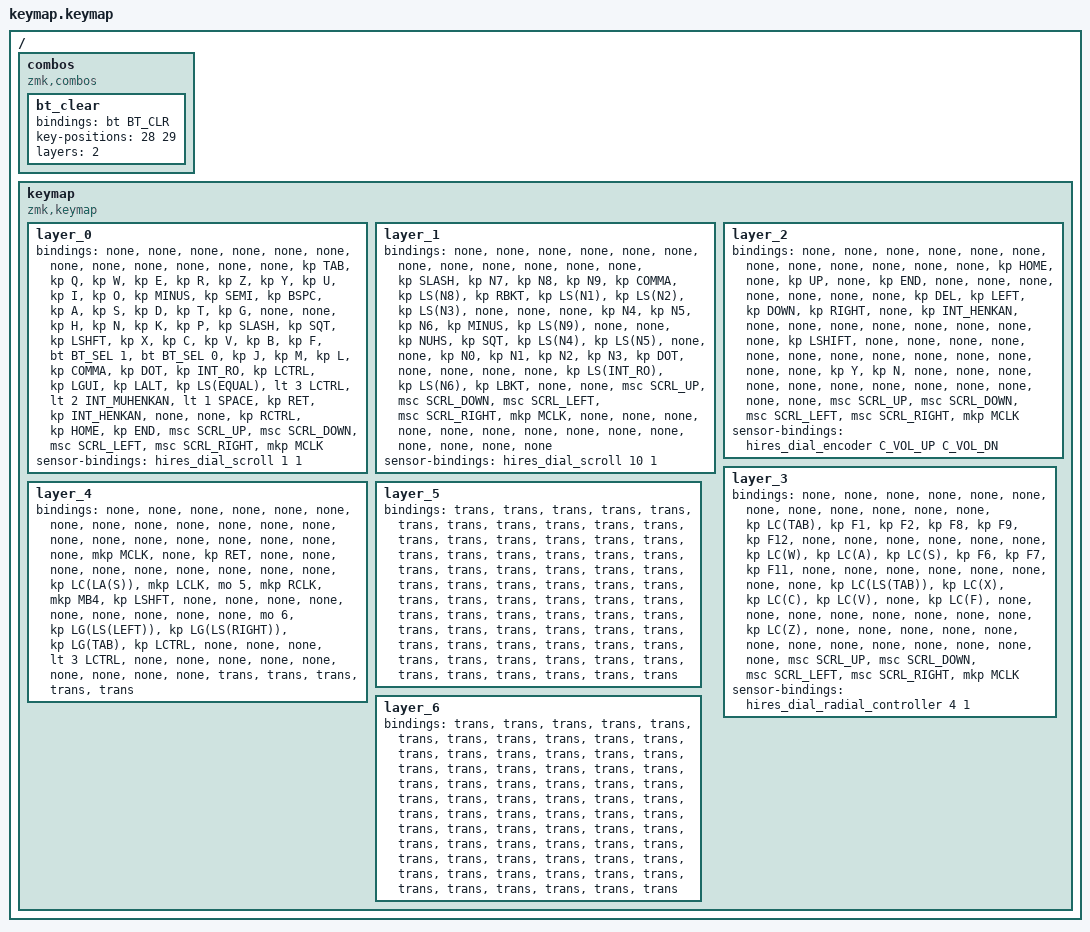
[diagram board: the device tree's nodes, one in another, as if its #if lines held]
#include <behaviors.dtsi>
#include <dt-bindings/zmk/bt.h>
#include <dt-bindings/zmk/keys.h>
#include <dt-bindings/zmk/outputs.h>
#include <dt-bindings/zmk/pointing.h>

#if defined(TORABO_TSUKI_LP_INPUT_HIRES_DIAL)
#include <behaviors/hires_dial.dtsi>
#endif

// Custom torabo-tsuki LP (M) layout.
// Layers: 0=base, 1=symbols, 2=cursor, 3=shortcuts,
// 4=auto mouse, 5=vertical scroll, 6=horizontal scroll (internal layers).
// Layout follows the stock 66-slot L-format; M has no physical number row.
// Non-mouse slots on layer 4 are &none; temp-layer processor deactivates
// the layer on a key press unless its physical position is excluded.
/ {
    combos {
        compatible = "zmk,combos";

        bt_clear {
            bindings = <&bt BT_CLR>;
            key-positions = <28 29>;
            layers = <2>;
        };
    };

    keymap {
        compatible = "zmk,keymap";

        layer_0 {
            bindings = <
            &none  &none  &none  &none  &none  &none  &none  &none  &none  &none  &none  &none
            &kp TAB  &kp Q  &kp W  &kp E  &kp R  &kp Z  &kp Y  &kp U  &kp I  &kp O  &kp MINUS  &kp SEMI
            &kp BSPC  &kp A  &kp S  &kp D  &kp T  &kp G  &none  &none  &kp H  &kp N  &kp K  &kp P  &kp SLASH  &kp SQT
            &kp LSHFT  &kp X  &kp C  &kp V  &kp B  &kp F  &bt BT_SEL 1  &bt BT_SEL 0  &kp J  &kp M  &kp L  &kp COMMA  &kp DOT  &kp INT_RO
            &kp LCTRL  &kp LGUI  &kp LALT  &kp LS(EQUAL)  &lt 3 LCTRL  &lt 2 INT_MUHENKAN  &lt 1 SPACE  &kp RET  &kp INT_HENKAN  &none  &none  &kp RCTRL  &kp HOME  &kp END
#if defined(TORABO_TSUKI_LP_KSCAN_4_DIRECTION_SWITCH)
&msc SCRL_UP &msc SCRL_DOWN &msc SCRL_LEFT &msc SCRL_RIGHT &mkp MCLK
#elif defined(TORABO_TSUKI_LP_INPUT_HIRES_DIAL)
&mkp MCLK
#endif
            >;
        };

        layer_1 {
            bindings = <
            &none  &none  &none  &none  &none  &none  &none  &none  &none  &none  &none  &none
            &kp SLASH  &kp N7  &kp N8  &kp N9  &kp COMMA  &kp LS(N8)  &kp RBKT  &kp LS(N1)  &kp LS(N2)  &kp LS(N3)  &none  &none
            &none  &kp N4  &kp N5  &kp N6  &kp MINUS  &kp LS(N9)  &none  &none  &kp NUHS  &kp SQT  &kp LS(N4)  &kp LS(N5)  &none  &none
            &kp N0  &kp N1  &kp N2  &kp N3  &kp DOT  &none  &none  &none  &none  &kp LS(INT_RO)  &kp LS(N6)  &kp LBKT  &none  &none
#if defined(TORABO_TSUKI_LP_KSCAN_4_DIRECTION_SWITCH)
&msc SCRL_UP &msc SCRL_DOWN &msc SCRL_LEFT &msc SCRL_RIGHT &mkp MCLK
#elif defined(TORABO_TSUKI_LP_INPUT_HIRES_DIAL)
&mkp MCLK
#endif
            &none  &none  &none  &none  &none  &none  &none  &none  &none  &none  &none  &none  &none  &none
            >;
        };

        layer_2 {
            bindings = <
            &none  &none  &none  &none  &none  &none  &none  &none  &none  &none  &none  &none
            &kp HOME  &none  &kp UP  &none  &kp END  &none  &none  &none  &none  &none  &none  &none
            &kp DEL  &kp LEFT  &kp DOWN  &kp RIGHT  &none  &kp INT_HENKAN  &none  &none  &none  &none  &none  &none  &none  &none
            &kp LSHIFT  &none  &none  &none  &none  &none  &none  &none  &none  &none  &none  &none  &none  &none
            &kp Y  &kp N  &none  &none  &none  &none  &none  &none  &none  &none  &none  &none  &none  &none
#if defined(TORABO_TSUKI_LP_KSCAN_4_DIRECTION_SWITCH)
&msc SCRL_UP &msc SCRL_DOWN &msc SCRL_LEFT &msc SCRL_RIGHT &mkp MCLK
#elif defined(TORABO_TSUKI_LP_INPUT_HIRES_DIAL)
&kp C_MUTE
#endif
            >;
        };

        layer_3 {
            bindings = <
            &none  &none  &none  &none  &none  &none  &none  &none  &none  &none  &none  &none
            &kp LC(TAB)  &kp F1  &kp F2  &kp F8  &kp F9  &kp F12  &none  &none  &none  &none  &none  &none
            &kp LC(W)  &kp LC(A)  &kp LC(S)  &kp F6  &kp F7  &kp F11  &none  &none  &none  &none  &none  &none  &none  &none
            &kp LC(LS(TAB))  &kp LC(X)  &kp LC(C)  &kp LC(V)  &none  &kp LC(F)  &none  &none  &none  &none  &none  &none  &none  &none
            &kp LC(Z)  &none  &none  &none  &none  &none  &none  &none  &none  &none  &none  &none  &none  &none
#if defined(TORABO_TSUKI_LP_KSCAN_4_DIRECTION_SWITCH)
&msc SCRL_UP &msc SCRL_DOWN &msc SCRL_LEFT &msc SCRL_RIGHT &mkp MCLK
#elif defined(TORABO_TSUKI_LP_INPUT_HIRES_DIAL)
&hires_dial_radial_controller_button
#endif
            >;
        };

        layer_4 {
            bindings = <
            &none  &none  &none  &none  &none  &none  &none  &none  &none  &none  &none  &none
            &none  &none  &none  &none  &none  &none  &none  &none  &none  &mkp MCLK  &none  &kp RET
            &none  &none  &none  &none  &none  &none  &none  &none  &none  &kp LC(LA(S))  &mkp LCLK  &mo 5  &mkp RCLK  &mkp MB4
            &kp LSHFT  &none  &none  &none  &none  &none  &none  &none  &none  &none  &mo 6  &kp LG(LS(LEFT))  &kp LG(LS(RIGHT))  &kp LG(TAB)
            &kp LCTRL  &none  &none  &none  &lt 3 LCTRL  &none  &none  &none  &none  &none  &none  &none  &none  &none
#if defined(TORABO_TSUKI_LP_KSCAN_4_DIRECTION_SWITCH)
&trans &trans &trans &trans &trans
#elif defined(TORABO_TSUKI_LP_INPUT_HIRES_DIAL)
&trans
#endif
            >;
        };

        // Holding the "P" position on layer 4 activates vertical-only scroll.
        layer_5 {
            bindings = <
            &trans  &trans  &trans  &trans  &trans  &trans  &trans  &trans  &trans  &trans  &trans  &trans
            &trans  &trans  &trans  &trans  &trans  &trans  &trans  &trans  &trans  &trans  &trans  &trans
            &trans  &trans  &trans  &trans  &trans  &trans  &trans  &trans  &trans  &trans  &trans  &trans  &trans  &trans
            &trans  &trans  &trans  &trans  &trans  &trans  &trans  &trans  &trans  &trans  &trans  &trans  &trans  &trans
            &trans  &trans  &trans  &trans  &trans  &trans  &trans  &trans  &trans  &trans  &trans  &trans  &trans  &trans
#if defined(TORABO_TSUKI_LP_KSCAN_4_DIRECTION_SWITCH)
&trans &trans &trans &trans &trans
#elif defined(TORABO_TSUKI_LP_INPUT_HIRES_DIAL)
&trans
#endif
            >;
        };

        // Holding the physical "L" position on layer 4 activates horizontal-only scroll.
        layer_6 {
            bindings = <
            &trans  &trans  &trans  &trans  &trans  &trans  &trans  &trans  &trans  &trans  &trans  &trans
            &trans  &trans  &trans  &trans  &trans  &trans  &trans  &trans  &trans  &trans  &trans  &trans
            &trans  &trans  &trans  &trans  &trans  &trans  &trans  &trans  &trans  &trans  &trans  &trans  &trans  &trans
            &trans  &trans  &trans  &trans  &trans  &trans  &trans  &trans  &trans  &trans  &trans  &trans  &trans  &trans
            &trans  &trans  &trans  &trans  &trans  &trans  &trans  &trans  &trans  &trans  &trans  &trans  &trans  &trans
#if defined(TORABO_TSUKI_LP_KSCAN_4_DIRECTION_SWITCH)
&trans &trans &trans &trans &trans
#elif defined(TORABO_TSUKI_LP_INPUT_HIRES_DIAL)
&trans
#endif
            >;
        };

    };
};

#if defined(TORABO_TSUKI_LP_INPUT_HIRES_DIAL)
&{/keymap/layer_0} {
    sensor-bindings = <&hires_dial_scroll 1 1>;
};

&{/keymap/layer_1} {
    sensor-bindings = <&hires_dial_scroll 10 1>;
};

&{/keymap/layer_2} {
    sensor-bindings = <&hires_dial_encoder C_VOL_UP C_VOL_DN>;
};

&{/keymap/layer_3} {
    /* Quarter-speed Radial Controller motion: output/input = 1/4. */
    sensor-bindings = <&hires_dial_radial_controller 4 1>;
};
#endif
